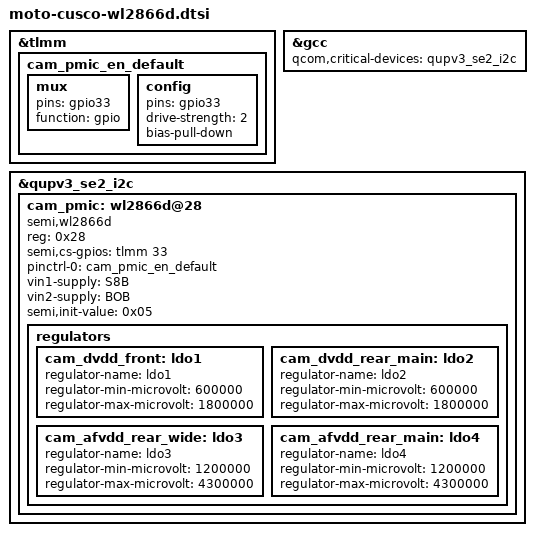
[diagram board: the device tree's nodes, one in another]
/*
 * Each QUP device that's a parent to PMIC must be listed as a critical device
 * to GCC.
 */

&tlmm{
	cam_pmic_en_default: cam_pmic_en_default {
		mux {
		pins = "gpio33";
		function = "gpio";
		};

		config {
		pins = "gpio33";
		drive-strength = <2>;
		bias-pull-down;
		};
	};
};

/*
 * Each QUP device that's a parent to PMIC must be listed as a critical device
 * to GCC.
 */
&gcc {
	qcom,critical-devices = <&qupv3_se2_i2c>;
};

&qupv3_se2_i2c {
	status = "ok";
	cam_pmic: wl2866d@28 {
		compatible = "semi,wl2866d";
		reg = <0x28>;

		semi,cs-gpios = <&tlmm 33 0>;
		pinctrl-names = "default";
		pinctrl-0 = <&cam_pmic_en_default>;

		vin1-supply = <&S8B>;
		vin2-supply = <&BOB>;
		semi,init-value = <0x05>;

		regulators {
			cam_dvdd_front: ldo1 {
				regulator-name = "ldo1";
				regulator-min-microvolt = <600000>;
				regulator-max-microvolt = <1800000>;
			};

			cam_dvdd_rear_main: ldo2 {
				regulator-name = "ldo2";
				regulator-min-microvolt = <600000>;
				regulator-max-microvolt = <1800000>;
			};

			cam_afvdd_rear_wide: ldo3 {
				regulator-name = "ldo3";
				regulator-min-microvolt = <1200000>;
				regulator-max-microvolt = <4300000>;
			};

			cam_afvdd_rear_main: ldo4 {
				regulator-name = "ldo4";
				regulator-min-microvolt = <1200000>;
				regulator-max-microvolt = <4300000>;
			};
		};
	};
};
